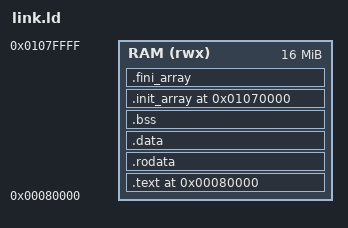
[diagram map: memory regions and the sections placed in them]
OUTPUT_ARCH("riscv")
ENTRY(_start)

MEMORY
{
    RAM (rwx) : ORIGIN = 0x80000, LENGTH = 16M
}

SECTIONS
{
    . = 0x80000;

    .text : {
        *(.text.init)
        *(.text .text.*)
    } > RAM

    .rodata : {
        *(.rodata .rodata.*)
    } > RAM

    .data : {
        __data_start = .;
        *(.data .data.*)
        *(.sdata .sdata.*)
        __data_end = .;
    } > RAM

    .bss : {
        __bss_start = .;
        *(.bss .bss.*)
        *(.sbss .sbss.*)
        *(COMMON)
        __bss_end = .;
    } > RAM

    . = ALIGN(16);
    __heap_start = .;

    . = ORIGIN(RAM) + LENGTH(RAM) - 0x10000;
    __stack_top = .;

    /* C++ sections */
    .init_array : {
        __init_array_start = .;
        KEEP(*(SORT_BY_INIT_PRIORITY(.init_array.*)))
        KEEP(*(.init_array))
        __init_array_end = .;
    } > RAM

    .fini_array : {
        __fini_array_start = .;
        KEEP(*(SORT_BY_INIT_PRIORITY(.fini_array.*)))
        KEEP(*(.fini_array))
        __fini_array_end = .;
    } > RAM
}
